# STM32MP25_CM33 register map
File version: 1.3
CPU: CM33 r0p1, little endian, MPU, FPU, vendor SysTick, 8 interrupt priority bits
Registers are 32-bit, read-write, reset 0x0 unless marked. A register's access mark holds for its fields unless they carry their own. Offsets are from the block's base; [hi:lo] are bit positions; {n}, {i} and the like mark numbered series.

## USB3DR (part 4 of 4) — USB3DR register block
Base 0x48300000
Same registers: USB3DR_S 0x58300000
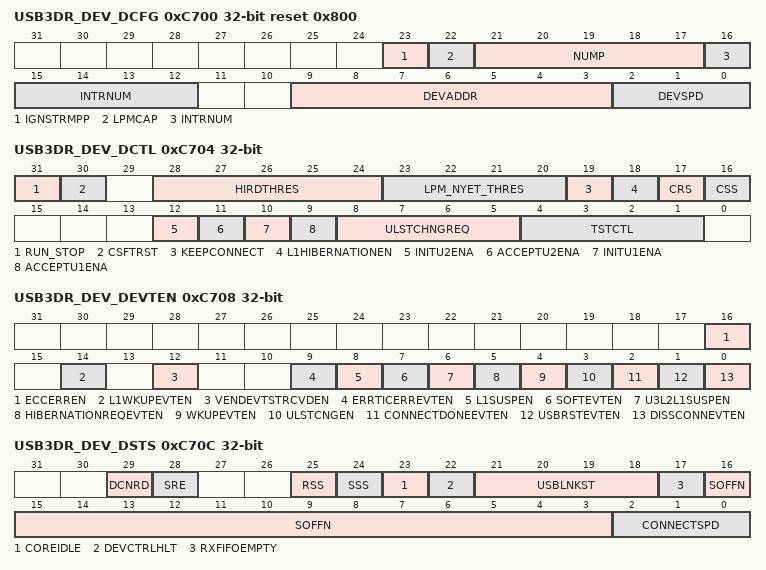
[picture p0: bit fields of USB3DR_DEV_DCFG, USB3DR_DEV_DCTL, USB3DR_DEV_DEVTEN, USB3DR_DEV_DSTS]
0xC700 USB3DR_DEV_DCFG reset 0x800 (reset mask 0x7F000C00) — USB3DR device configuration register
  [23] IGNSTRMPP — IgnoreStreamPP This bit only affects stream-capable bulk endpoints. When this bit is set to 0 and the controller receives a data packet with the packet pending (PP) bit set to 0 for OUT endpoints, or it receives an ACK with the NumP field set to 0 and PP set to 0 for IN endpoints, the core attempts to search for another stream (CStream) to initiate to the host. However, there are two situations where this behavior is not optimal: When the host is setting PP=0 even though it has not finished the stream, or When the endpoint on the device is configured with one transfer resource and therefore does not have any other streams to initiate to the host. When this bit is set to 1, the core ignores the packet pending bit for the purposes of stream selection and does not search for another stream when it receives DP(PP=0) or ACK(NumP=0, PP=0). This can enhance the performance when the device system bus bandwidth is low or the host responds to the core's ERDY transmission very quickly.
  [22] LPMCAP — LPM capable The application uses this bit to control the USB3DR LPM capabilities. If the USB3DR operates as a non-LPM-capable device, it cannot respond to LPM transactions.
    0=LPM capability is not enabled; 1=LPM capability is enabled
  [21:17] NUMP — Number of receive buffers. This bit indicates the number of receive buffers to be reported in the ACK TP. The USB3DR controller uses this field for non-control endpoints if GRXTHRCFG.UsbRxPktCntSel is set to 0. The application can program this value based on RxFIFO size, buffer sizes programmed in descriptors, and system latency. For an OUT endpoint, this field controls the number of receive buffers reported in the NumP field of the ACK TP transmitted by the core. Note: This bit is used in host mode when debug capability is enabled.
  [16:12] INTRNUM — Interrupt number Indicates interrupt/EventQ number on which non-endpoint-specific device-related interrupts (see DEVT) are generated.
  [9:3] DEVADDR — Device address. The application must perform the following: Program this field after every SetAddress request. Reset this field to zero after USB reset.
  [2:0] DEVSPD — Device speed. Indicates the speed at which the application requires the core to connect, or the maximum speed the application can support. However, the actual bus speed is determined only after the chirp sequence is completed, and is based on the speed of the USB host to which the core is connected.
    4=SuperSpeed (USB 3.0 PHY clock is 125MHz or 250MHz); 0=High-speed (USB 2.0 PHY clock is 30MHz or 60MHz); 1=Full-speed (USB 2.0 PHY clock is 30MHz or 60MHz)
0xC704 USB3DR_DEV_DCTL (reset mask 0x2000E001) — USB3DR device control register
  [31] RUN_STOP — Run/stop The software writes 1 to this bit to start the device controller operation. To stop the device controller operation, the software must remove any active transfers and write 0 to this bit. When the controller is stopped, it sets the DSTS.DevCtrlHlt bit when the core is idle and the lower layer finishes the disconnect process. The run/stop bit must be used in following cases as specified: After power-on reset and CSR initialization, the software must write 1 to this bit to start the device controller. The controller does not signal connection to the host until this bit is set. The software uses this bit to control the device controller to perform a soft disconnect. When the software writes 0 to this bit, the host does not see that the device is connected. The device controller stays in the disconnected state until the software writes 1 to this bit. The minimum duration of keeping this bit cleared is specified in the Note: below. If the software attempts a connect after the soft disconnect or detects a disconnect event, it must set DCTL[8:5] to 5 before reasserting the run/stop bit. When the USB or Link is in a lower power state and the two power rails configuration is selected, software writes 0 to this bit to indicate that it is going to turn off the core power rail. After the software turns on the core power rail again and re-initializes the device controller, it must set this bit to start the device controller. Note: The following is the minimum duration under various conditions for which the soft disconnect (SftDiscon) bit must be set for the USB host to detect a device disconnect: Note: 30ms: For SuperSpeed, when the device state is suspended, idle, transmit, or receive. Note: 10ms: For high-speed, when the device state is suspended, idle, or not idle/suspended (performing transactions). Note: For full-speed/low-speed, when the device state is suspended, idle, or not idle/supended (performing transactions). Note: To accommodate clock jitter, it is recommended that the application adds extra delay to the specified minimum duration.
  [30] CSFTRST — Core soft reset Resets the all clock domains as follows: This bit clears the interrupts and all the CSRs except GSTS, GSNPSID, GGPIO, GUID, GUSB2PHYCFGn registers, GUSB3PIPECTLn registers, DCFG, DCTL, DEVTEN, and DSTS registers. All module state machines (except the device bus slave unit) are reset to the idle state, and all the TxFIFOs and the RxFIFO are flushed. Any transactions on the device bus master are terminated as soon as possible, after gracefully completing the last data phase of a device bus transfer. Any transactions on the USB are terminated immediately. The application can write this bit at any time to reset the core. This is a self-clearing bit; the core clears this bit after all necessary logic is reset in the core, which may take several clocks depending on the core current state. Once this bit is cleared, the software must wait at least 3 PHY clocks before accessing the PHY domain (synchronization delay). Typically, software reset is used during software development and also when the PHY selection bits are dynamically changed in the USB configuration registers listed above. When the PHY is changed, the corresponding clock for the PHY is selected and used in the PHY domain. Once a new clock is selected, the PHY domain must be reset for proper operation. Note: Programming this field with random data causes side effect. Bit bash register testing is not recommended.
  [28:24] HIRDTHRES — HIRD threshold (HIRD_Thres) The core asserts output signals utmi_l1_suspend_n and utmi_sleep_n on the basis of this signal: The core asserts utmi_l1_suspend_n to put the PHY into deep Low-power mode in L1 when both of the following are true: HIRD value is greater than or equal to the value in DCTL.HIRD_Thres[3:0] HIRD_Thres[4] is set to 1. The core asserts utmi_sleep_n on L1 when one of the following is true: If the HIRD value is less than HIRD_Thres[3:0] or HIRD_Thres[4] is set to 0. Note: This field must be set to 0 during SuperSpeed mode of operation.
  [23:20] LPM_NYET_THRES — LPM NYET threshold When LPM errata is enabled: Bits [23:20]: LPM NYET response threshold (LPM_NYET_thres) Handshake response to LPM token specified by device application. Response depends on DCFG.LPMCap. DCFG.LPMCap is 0 - The core always responds with timeout (that is, no response). DCFG.LPMCap is 1 - The core responds with an ACK on successful LPM transaction, which requires that all of the following are satisfied: There are no PID or CRC5 errors in both the EXT token and the LPM token (if not true, inactivity results in a timeout ERROR). No data is pending in the TxFIFO and RxFIFO is empty (else NYET). The BESL value in the LPM token is less than or equal to LPM_NYET_thres[3:0]
  [19] KEEPCONNECT — Keep connect When 1, this bit enables the save and restore programming model by preventing the core from disconnecting from the host when DCTL.RUN_STOP is set to 0. It also enables the hibernation request event to be generated when the link goes to U3 or L2. The device core disconnects from the host when DCTL.RUN_STOP is set to 0. This bit indicates whether to preserve this behavior (0), or if the core must not disconnect when run/stop is set to 0 (1). This bit also prevents the LTSSM from automatically going to U0/L0 when the host requests resume from U3/L2. Note: If hibernation is disabled, that is, GCTL[1].GblHibernationEn=0, this bit is tied to zero.
  [18] L1HIBERNATIONEN — L1HibernationEn When this bit is set along with KeepConnect, the device core generates a hibernation request event if L1 is enabled and the HIRD value in the LPM token is larger than the threshold programmed in DCTL.HIRD_Thres. The core does not exit the LPM L1 state until the software writes recovery into the DCTL.ULStChngReq field. This prevents corner cases where the device is entering hibernation at the same time the host is attempting to exit L1. Note: If hibernation is disabled, that is, GCTL[1].GblHibernationEn=0, this bit is tied to zero.
  [17] CRS — Controller restore state (CRS) This command is similar to the USBCMD.CRS bit in host mode and initiates the restore process. When software sets this bit to 1, the controller immediately sets DSTS.RSS to 1. When the controller has finished the restore process, it sets DSTS.RSS to 0. Note: When read, this field always returns 0.
  [16] CSS — Controller save state (CSS) This command is similar to the USBCMD.CSS bit in host mode and initiates the save process. When the software sets this bit to 1, the controller immediately sets DSTS.SSS to 1. When the controller has finished the save process, it sets DSTS.SSS to 0' Note: When read, this field always returns 0.
  [12] INITU2ENA — Initiate U2 enable On USB reset, the hardware clears this bit to 0. The software sets this bit after receiving SetFeature(U2_ENABLE), and clears this bit when ClearFeature(U2_ENABLE) is received. If DCTL[11] (AcceptU2Ena) is 0, the link immediately exits U2 state.
    0=May not initiate U2 (default); 1=May initiate U2
  [11] ACCEPTU2ENA — Accept U2 enable On USB reset, the hardware clears this bit to 0. The software sets this bit after receiving a SetConfiguration command.
    0=The core reject U2 except when Force_LinkPM_Accept bit is set (default); 1=The core accepts transition to U2 state if nothing is pending on the application side
  [10] INITU1ENA — Initiate U1 enable On USB reset, the hardware clears this bit to 0. The software sets this bit after receiving SetFeature(U1_ENABLE), and clears this bit when ClearFeature(U1_ENABLE) is received. If DCTL[9] (AcceptU1Ena) is 0, the link immediately exits U1 state.
    0=May not initiate U1 (default);; 1=May initiate U1
  [9] ACCEPTU1ENA — Accept U1 enable On USB reset, the hardware clears this bit to 0. The software sets this bit after receiving a SetConfiguration command.
    0=The core rejects U1 except when Force_LinkPM_Accept bit is set (default); 1=The core accepts transition to U1 state if nothing is pending on the application side
  [8:5] ULSTCHNGREQ wo — ULSTCHNGREQ Software writes this field to issue a USB/Link state change request. A change in this field indicates a new request to the core. If the software wants to issue the same request back-to-back, it must write a 0 to this field between the two requests. The result of the state change request is reflected in the USB/Link state in DSTS. These bits are self-cleared on the MAC layer exiting suspended state. If the software is updating other fields of the DCTL register and not intending to force any link state change, then it must write a 0 to this field. SS Compliance mode is normally entered and controlled by the remote link partner. Refer to [USB3]. Alternatively, the local link can be forced directly into compliance mode, by resetting the SS link with the run/stop bit set to zero. If 10 is then written to the USB/Link state change field and 1 to run/stop, the link goes to compliance mode. Once in compliance, zero and 10 may be alternatively written to this field to advance the compliance pattern. Condition: in SS mode, the values for link state transition/action are: Others: Reserved Condition: in HS/FS/LS mode, the values for link state transition/action are: Others: Reserved The remote wakeup request must be issued 2us after the device goes into suspend state (DSTS[21:18] is 3. Note: After coming out of hibernation, the software must write 8 (recovery) into this field to confirm exit from the suspended state.
    0=No action; 2=Compliance
  [4:1] TSTCTL — Test control Others: Reserved
    0=Test mode disabled; 1=Test_J mode; 2=Test_K mode; 3=Test_SE0_NAK mode; 4=Test_Packet mode; 5=Test_Force_Enable
0xC708 USB3DR_DEV_DEVTEN (reset mask 0xFFFE0C00) — USB3DR device event enable register
  [16] ECCERREN ro — ECC error enable. If this bit is set to 1, the controller reports an ECC error to the software when an uncorrectable ECC occurs internally.
  [14] L1WKUPEVTEN — L1 resume detected event enable. Note: If GUCTL1[DEV_DECOUPLE_L1L2_EVT] is enabled, then this bit is for L1 resume detected event enable.
  [12] VENDEVTSTRCVDEN — Vendor device Test LMP received event (VndrDevTstRcvedEn)
  [9] ERRTICERREVTEN — Erratic error event enable
  [8] L1SUSPEN — L1 suspend event enable Note: Only if GUCTL1[DEV_DECOUPLE_L1L2_EVT] is enabled, this bit is for L1 suspend event enable.
  [7] SOFTEVTEN — Start of (u)frame
  [6] U3L2L1SUSPEN — U3/L2 or U3/L2L1 suspend event enable. Note: If GUCTL1[DEV_DECOUPLE_L1L2_EVT] is enabled, then this bit is for U3/L2 suspend event enable. Note: If GUCTL1[DEV_DECOUPLE_L1L2_EVT] is not enabled, then this bit is for U3/L2L1 suspend event enable.
  [5] HIBERNATIONREQEVTEN — This bit enables/disables the generation of the hibernation request event.
  [4] WKUPEVTEN — U3/L2 or U3/L2L1 resume detected event enable. Note: If GUCTL1[DEV_DECOUPLE_L1L2_EVT] is enabled, then this bit is for U3/L2 resume detected event enable. Note: If GUCTL1[DEV_DECOUPLE_L1L2_EVT] is not enabled, then this bit is for U3/L2L1 resume detected event enable.
  [3] ULSTCNGEN — USB/Link state change event enable
  [2] CONNECTDONEEVTEN — Connection done enable
  [1] USBRSTEVTEN — USB reset enable
  [0] DISSCONNEVTEN — Disconnect detected event enable
0xC70C USB3DR_DEV_DSTS (reset mask 0xDC000000) — USB3DR device status register
  [29] DCNRD ro — Device controller not ready The bit indicates that the core is in the process of completing the state transitions after exiting from hibernation. To complete the state transitions, it takes 256 bus clock cycles from the time DCTL[31].RUN_STOP is set. During hibernation, if the UTMI/ULPI PHY is in suspended state, then the 256-bus clock cycle delay starts after the PHY exited suspended state. The software must set DCTL[31].RUN_STOP to 1 and wait for this bit to be de-asserted to zero before processing DSTS.USBLnkSt. This bit is valid only when USB3DR_EN_PWROPT is set to 2 and GCTL[1].GblHibernationEn=1.
  [28] SRE — Save restore error Currently not supported.
  [25] RSS ro — RSS restore state status This bit is similar to the USBSTS.RSS in Host mode. When the controller finishes the restore process, it completes the command by setting DSTS.RSS to 0.
  [24] SSS ro — SSS save state status This bit is similar to the USBSTS.SSS in Host mode. When the controller has finished the save process, it completes the command by setting DSTS.SSS to 0.
  [23] COREIDLE ro — Core idle The bit indicates that the core finished transferring all RxFIFO data to system memory, writing out all completed descriptors, and all event counts are zero. Note: While testing for reset values, mask out the read value. This bit represents the changing state of the core and does not hold a static value.
  [22] DEVCTRLHLT ro — Device controller halted This bit is set to 0 when the run/stop bit in the DCTL register is set to 1. The core sets this bit to 1 when, after the software sets run/stop to 0, the core is idle and the lower layer finishes the disconnect process. When Halted=1, the core does not generate Device events. Note: The core does not set this bit to 1 if GEVNTCOUNTn has some valid value. Software needs to acknowledge the events that are generated (by writing to GEVNTCOUNTn) while it is waiting for this bit to be set to 1. Note: When interrupt moderation is enabled, there may be delay in raising the interrupt line when the event count is non-zero. Software should read the GEVNTCOUNT register directly and acknowledge them.
  [21:18] USBLNKST ro — USBLNKST USB/Link state Condition: in HS FS LS mode: The link state resume/reset indicates that the core received a resume or USB reset request from the host while the link was in hibernation. The software must write 8 (recovery) to the DCTL.ULStChngReq field to acknowledge the resume/reset request. When hibernation is enabled, GCTL[1].GblHibernationEn=1, this field USBLnkSt is valid only when DCTL[31].RUN_STOP is set to 1 and DSTS[29].DCNRD=0. Note: If SSIC is enabled, while exiting a low power state, the USBLnkSt field indicates resume/reset even for a disconnect condition because a resume precedes the disconnect.
    0=B_0x0_IN_SS_MODE_LTSSM_STATE (On state); 1=B_0x1_IN_SS_MODE_LTSSM_STATE (U1); 2=B_0x2_IN_SS_MODE_LTSSM_STATE (Sleep (L1) state); 3=B_0x3_IN_SS_MODE_LTSSM_STATE (Suspend (L2) state); 4=B_0x4_IN_SS_MODE_LTSSM_STATE (Disconnected state (default state)); 5=B_0x5_IN_SS_MODE_LTSSM_STATE (Early suspend state (valid only when hibernation is disabled, GCTL[1].GblHibernationEn=0)); 6=B_0x6_IN_SS_MODE_LTSSM_STATE (SS_INACT); 7=B_0x7_IN_SS_MODE_LTSSM_STATE (POLL); 8=B_0x8_IN_SS_MODE_LTSSM_STATE (RECOV); 9=B_0x9_IN_SS_MODE_LTSSM_STATE (HRESET); 10=B_0xA_IN_SS_MODE_LTSSM_STATE (CMPLY); 11=B_0xB_IN_SS_MODE_LTSSM_STATE (LPBK); 15=B_0xF_IN_SS_MODE_LTSSM_STATE (Resume (valid only when hibernation is enabled, GCTL[1].GblHibernationEn=1)); 14=B_0xE_IN_SS_MODE_LTSSM_STATE (Reset (valid only when hibernation is enabled, GCTL[1].GblHibernationEn=1))
  [17] RXFIFOEMPTY ro
  [16:3] SOFFN ro — Frame/Microframe number of the received SOF. When the core is operating at SuperSpeed, [16:3] indicates the uframe/ITP number When the core is operating at high-speed, [16:6] indicates the frame number [5:3] indicates the micro-frame number When the core is operating at full-speed, [16:14] is not used, the software can ignore these 3 bits [13:3] indicates the frame number
  [2:0] CONNECTSPD ro — Connected speed (ConnectSpd) Indicates the speed at which the USB3DR has come up after speed detection through a chirp sequence. Low-speed is not supported for devices using a UTMI+ PHY.
    4=SuperSpeed (PHY clock is running at 125 or 250MHz); 0=High-speed (PHY clock is running at 30 or 60MHz); 1=Full-speed (PHY clock is running at 30 or 60MHz)
0xC710 USB3DR_DEV_DGCMDPAR — USB3DR device generic command parameter register
  [31:0] PARAMETER
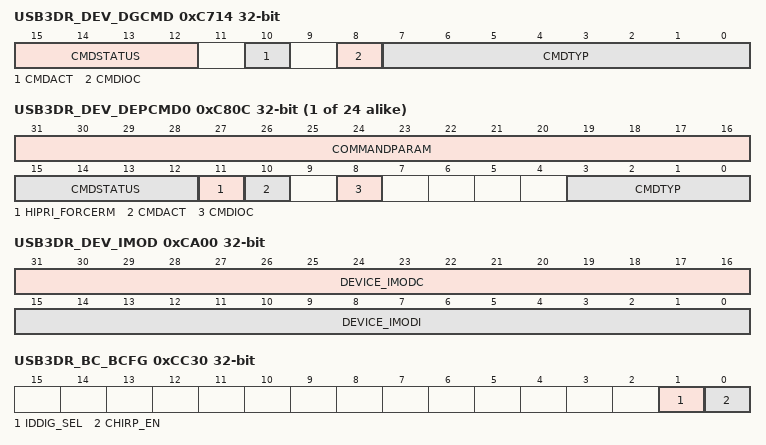
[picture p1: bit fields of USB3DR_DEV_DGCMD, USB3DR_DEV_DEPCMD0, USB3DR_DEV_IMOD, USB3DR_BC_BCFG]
0xC714 USB3DR_DEV_DGCMD (reset mask 0xFFFF0A00) — USB3DR device generic command register
  [15:12] CMDSTATUS ro — Command status
    1=CmdErr, indicates that the device controller encountered an error while processing the command; 0=Indicates command success
  [10] CMDACT — Command active The software sets this bit to 1 to enable the device controller to execute the generic command. The device controller sets this bit to 0 after executing the command.
  [8] CMDIOC — Command interrupt on complete When this bit is set, the device controller issues a generic command completion event after executing the command. Note: This interrupt is mapped to DCFG.IntrNum. Note: This field must not set to 1 if the DCTL.RUN_STOP field is 0.
  [7:0] CMDTYP — Generic command type Specifies the type of generic command the software driver is requesting the controller to perform. All other values are reserved.
    2=Set periodic parameters; 4=Set scratchpad buffer array address low; 5=Set scratchpad buffer array address high; 7=Transmit device notification; 9=Selected FIFO flush; 10=All FIFO flush; 12=Set endpoint NRDY; 16=Run device bus loopback test; 17=Restart after disconnect
0xC720 USB3DR_DEV_DALEPENA — USB3DR device active USB endpoint enable register
  [31:0] USBACTEP — USBACTEP USB active endpoints (USBActEP) This field indicates if a USB endpoint is active in the current configuration and interface. It applies to USB IN endpoints 0.15 and OUT endpoints 0.15, with one bit for each of the 32 possible endpoints. Even numbers are for USB OUT endpoints, and odd numbers are for USB IN endpoints, as follows: Bit[0]: USB EP0-OUT Bit[1]: USB EP0-IN Bit[2]: USB EP1-OUT Bit[3]: USB EP1-IN The entity programming this register must set bits 0 and 1 because they enable control endpoints that map to physical endpoints (resources) after USBReset. Hardware clears these bits for all endpoints (other than EP0-OUT and EP0-IN) after detecting a USB reset event. After receiving SetConfiguration and SetInterface requests, the application must program endpoint registers accordingly and set these bits.
0xC800 USB3DR_DEV_DEPCMDPAR20 — USB3DR device physical endpoint-n command parameter 2 register
  [31:0] PARAMETER
0xC804 USB3DR_DEV_DEPCMDPAR10 — USB3DR device physical endpoint-n command parameter 1 register
  [31:0] PARAMETER
{0xC808+0x10*i} USB3DR_DEV_DEPCMDPAR{i:02} (i=0..9) — USB3DR device physical endpoint-n command parameter 0 register
  [31:0] PARAMETER
{0xC80C+0x10*i} USB3DR_DEV_DEPCMD{i} (i=0..23) — USB3DR device physical endpoint-n command register
  [31:16] COMMANDPARAM — Command parameters or event parameters Command parameters (CommandParam), when this register is written: For start transfer command: [31:16]: StreamID. The USB StreamID assigned to this transfer For start transfer command applied to an isochronous endpoint [31:16]: StartMicroFramNum: indicates the (micro-)frame number to which the first TRB applies. For update transfer, end transfer, and start new configuration commands [22:16]: Transfer resource index (XferRscIdx). The hardware-assigned transfer resource index for the transfer, which was returned in response to the start transfer command. The application software-assigned transfer resource index for a start new configuration command. Event parameters (EventParam), when this register is read.
  [15:12] CMDSTATUS — Command completion status (CmdStatus) Additional information about the completion of this command is available in this field. The information is in the same format as bits 15:12 of the endpoint command complete event.
  [11] HIPRI_FORCERM — HighPriority/ForceRM (HiPri_ForceRM) HighPriority: only valid for start transfer command ForceRM: only valid for end transfer command ClearPendIN: only valid for clear stall command. The software sets this bit to clear any pending IN transaction (on that endpoint) stuck at the lower layers when a clear stall command is issued.
  [10] CMDACT — Command active (CmdAct) Software sets this bit to 1 to enable the device endpoint controller to execute the generic command. The device controller sets this bit to 0 when the CmdStatus field is valid and the endpoint is ready to accept another command. This does not imply that all the effects of the previously-issued command have taken place.
  [8] CMDIOC — CMDIOC Command interrupt on complete (CmdIOC) When this bit is set, the device controller issues a generic endpoint command complete event after executing the command. Note: This interrupt is mapped to DEPCFG.IntrNum. When the DEPCFG command is executed, the command interrupt on completion goes to the interrupt pointed by the DEPCFG.IntrNum in the current command. Note: This field must not set to 1 if the DCTL.RUN_STOP field is 0.
  [3:0] CMDTYP — Command type Specifies the type of command the software driver is requesting the core to perform. 0x09 Start new configuration, no parameter needed
    1=Set endpoint configuration, 64 or 96-bit parameter; 2=Set endpoint transfer resource configuration, 32-bit parameter; 3=Get endpoint state, no parameter needed; 4=Set stall, no parameter needed; 5=Clear stall (see set stall), no parameter needed; 6=Start transfer, 64-bit parameter; 7=Update transfer, no parameter needed; 8=End transfer, no parameter needed
0xC810 USB3DR_DEV_DEPCMDPAR21 — USB3DR device physical endpoint-n command parameter 2 register
  [31:0] PARAMETER
0xC814 USB3DR_DEV_DEPCMDPAR11 — USB3DR device physical endpoint-n command parameter 1 register
  [31:0] PARAMETER
0xC820 USB3DR_DEV_DEPCMDPAR22 — USB3DR device physical endpoint-n command parameter 2 register
  [31:0] PARAMETER
0xC824 USB3DR_DEV_DEPCMDPAR12 — USB3DR device physical endpoint-n command parameter 1 register
  [31:0] PARAMETER
0xC830 USB3DR_DEV_DEPCMDPAR23 — USB3DR device physical endpoint-n command parameter 2 register
  [31:0] PARAMETER
0xC834 USB3DR_DEV_DEPCMDPAR13 — USB3DR device physical endpoint-n command parameter 1 register
  [31:0] PARAMETER
{0xC6C0+0x10*i} USB3DR_DEV_DEPCMDPAR{i} (i=24..29) — USB3DR device physical endpoint-n command parameter 2 register
  [31:0] PARAMETER
0xC844 USB3DR_DEV_DEPCMDPAR14 — USB3DR device physical endpoint-n command parameter 1 register
  [31:0] PARAMETER
0xC854 USB3DR_DEV_DEPCMDPAR15 — USB3DR device physical endpoint-n command parameter 1 register
  [31:0] PARAMETER
0xC864 USB3DR_DEV_DEPCMDPAR16 — USB3DR device physical endpoint-n command parameter 1 register
  [31:0] PARAMETER
0xC874 USB3DR_DEV_DEPCMDPAR17 — USB3DR device physical endpoint-n command parameter 1 register
  [31:0] PARAMETER
0xC884 USB3DR_DEV_DEPCMDPAR18 — USB3DR device physical endpoint-n command parameter 1 register
  [31:0] PARAMETER
0xC894 USB3DR_DEV_DEPCMDPAR19 — USB3DR device physical endpoint-n command parameter 1 register
  [31:0] PARAMETER
{0xBB80+0x10*i} USB3DR_DEV_DEPCMDPAR{i} (i=210..223) — USB3DR device physical endpoint-n command parameter 2 register
  [31:0] PARAMETER
{0xC1C4+0x10*i} USB3DR_DEV_DEPCMDPAR{i} (i=110..123) — USB3DR device physical endpoint-n command parameter 1 register
  [31:0] PARAMETER
0xC8A8 USB3DR_DEV_DEPCMDPAR010 — USB3DR device physical endpoint-n command parameter 0 register
  [31:0] PARAMETER
0xC8B8 USB3DR_DEV_DEPCMDPAR011 — USB3DR device physical endpoint-n command parameter 0 register
  [31:0] PARAMETER
0xC8C8 USB3DR_DEV_DEPCMDPAR012 — USB3DR device physical endpoint-n command parameter 0 register
  [31:0] PARAMETER
0xC8D8 USB3DR_DEV_DEPCMDPAR013 — USB3DR device physical endpoint-n command parameter 0 register
  [31:0] PARAMETER
0xC8E8 USB3DR_DEV_DEPCMDPAR014 — USB3DR device physical endpoint-n command parameter 0 register
  [31:0] PARAMETER
0xC8F8 USB3DR_DEV_DEPCMDPAR015 — USB3DR device physical endpoint-n command parameter 0 register
  [31:0] PARAMETER
0xC908 USB3DR_DEV_DEPCMDPAR016 — USB3DR device physical endpoint-n command parameter 0 register
  [31:0] PARAMETER
0xC918 USB3DR_DEV_DEPCMDPAR017 — USB3DR device physical endpoint-n command parameter 0 register
  [31:0] PARAMETER
0xC928 USB3DR_DEV_DEPCMDPAR018 — USB3DR device physical endpoint-n command parameter 0 register
  [31:0] PARAMETER
0xC938 USB3DR_DEV_DEPCMDPAR019 — USB3DR device physical endpoint-n command parameter 0 register
  [31:0] PARAMETER
0xC948 USB3DR_DEV_DEPCMDPAR020 — USB3DR device physical endpoint-n command parameter 0 register
  [31:0] PARAMETER
0xC958 USB3DR_DEV_DEPCMDPAR021 — USB3DR device physical endpoint-n command parameter 0 register
  [31:0] PARAMETER
0xC968 USB3DR_DEV_DEPCMDPAR022 — USB3DR device physical endpoint-n command parameter 0 register
  [31:0] PARAMETER
0xC978 USB3DR_DEV_DEPCMDPAR023 — USB3DR device physical endpoint-n command parameter 0 register
  [31:0] PARAMETER
0xCA00 USB3DR_DEV_IMOD — USB3DR device interrupt moderation register
  [31:16] DEVICE_IMODC — Interrupt moderation down counter Loaded with the DEVICE_IMODI value, whenever the hardware interrupt(n) line is de-asserted from the asserted state, counts down to 0, and stops. The interrupt(n) is signaled whenever this counter is 0, EVNT_HANDLER_BUSY is 0, and there are pending events (that is, event count is non-zero). This counter may be directly written by software at any time to alter the interrupt rate.
  [15:0] DEVICE_IMODI — Moderation interval (DEVICE_IMODI) This field holds the minimum inter-interrupt interval between events. The interval is specified in 250ns increments. A value of 0 disables the interrupt throttling logic and interrupts are generated immediately if event count becomes non-zero. In scale down simulation mode, 4 ram clocks are used to time 250ns.
0xCC30 USB3DR_BC_BCFG (reset mask 0xFFFFFFFC) — USB3DR battery charger configuration register
  [1] IDDIG_SEL — IDDIG select When this bit is programmed as: When ULPI PHY is used, IDDIG_SEL needs to be programmed to 0 always, so that the core uses the ID value obtained from the RX_CMD.
    1=The core determines the ID pin value from RID_A and RID_GND inputs of the battery charger; 0=The core determines ID pin value from utmiotg_iddig input
  [0] CHIRP_EN — Chirp enable When this bit is 1, the core asserts the bc_chirp_on output signal to indicate an imminent chirp.
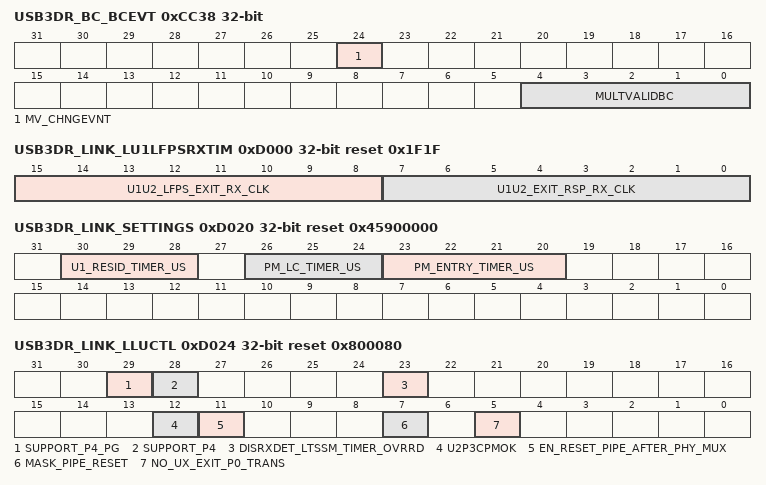
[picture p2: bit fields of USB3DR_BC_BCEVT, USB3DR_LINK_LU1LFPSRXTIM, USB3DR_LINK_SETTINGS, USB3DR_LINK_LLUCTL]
0xCC38 USB3DR_BC_BCEVT — USB3DR battery charger event register
  [24] MV_CHNGEVNT — Multi-valued input changed event: This event indicates that there is a change in the value of at least one ACA pin value. This bit is present only if USB3DR_EN_BC=1, otherwise it is Reserved.
  [4:0] MULTVALIDBC ro — Multi valued ID pin Indicates the battery charger ACA inputs. MultValIdBc[4]: bc_rid_float MultValIdBc[3]: bc_rid_gnd MultValIdBc[2]: bc_rid_a MultValIdBc[1]: bc_rid_b MultValIdBc[0]: bc_rid_c
0xCC3C USB3DR_BC_BCEVTEN (reset mask 0xFEFFFFFF) — USB3DR battery charger event enable register
  [24] MV_CHNGEVNTENA — BCEvtInfoEna[0] Multi-valued input changed event enable (MV_ChngEvntEn) When this bit is set, MV_ChngEvnt in BCEVT register is enabled.
0xD000 USB3DR_LINK_LU1LFPSRXTIM reset 0x1F1F — USB3DR U1/U2 LFPS RX timer register
  [15:8] U1U2_LFPS_EXIT_RX_CLK — Programmable U1U2 LFPS EXIT RX CLKS Applicable to remote partner initiated Ux exit: time to recognize valid Ux exit request from the remote partner. This field is encoded as the pipe clk (8ns) count for the LFPS.
    1=8ns
  [7:0] U1U2_EXIT_RSP_RX_CLK — Programmable U1U2 EXIT RESP RX CLKS Applicable to locally initiated Ux exit: minimum LFPS reception from remote to consider Ux exit handshake is successful. This field is encoded as the pipe clk (8ns) count for the LFPS.
    1=8ns
0xD020 USB3DR_LINK_SETTINGS reset 0x45900000 — USB3DR link setting register
  [30:28] U1_RESID_TIMER_US — Programmable U1 MIN RESIDENCY TIMER This field specifies U1 MIN RESIDENCY TIMER value in us. Set to 0 to disable the timer.
  [26:24] PM_LC_TIMER_US — Programmable PM_LC_TIMER This field specifies PM_LC_TIMER value in us.
  [23:20] PM_ENTRY_TIMER_US — Programmable PM_ENTRY_TIMER This field specifies PM_ENTRY_TIMER value in us.
0xD024 USB3DR_LINK_LLUCTL reset 0x800080 — USB3DR link user control register
  [29] SUPPORT_P4_PG — PHY P4 power gate mode (PG) is enabled. Set this bit if the PHY supports PG mode in P4. This bit is used only for Synopsys PHY.
  [28] SUPPORT_P4 — Support PHY P3.CPM and P4 power states. When this bit is set, the controller puts the PHY in P3.CPM or P4 in certain states. This bit is used only for Synopsys PHY.
  [23] DISRXDET_LTSSM_TIMER_OVRRD — DisRxDet_LTSSM_Timer_Ovrrd. When DisRxDetU3RxDet is asserted in polling or U1, the timeout expires immediately.
  [12] U2P3CPMOK — P3CPM OK for U2/SSInactive (U2P3CPMok) Note: For a port, if both GUCTL1[25]=1 and LUCTL[12]=1, LUCTL[12]=1 takes priority.
    0=During link state U2/SS.Inactive, put PHY in P2 (default); 1=During link state U2/SS.Inactive, put PHY in P3CPM
  [11] EN_RESET_PIPE_AFTER_PHY_MUX — en_reset_pipe_after_phy_mux. The controller issues USB 3.0 PHY reset after DisRxDetU3RxDet is de-asserted.
  [7] MASK_PIPE_RESET — Mask pipe reset. If this bit is set, controller blocks pipe_reset_n from going to the PHY when DisRxDetU3RxDet=1.
  [5] NO_UX_EXIT_P0_TRANS — no_ux_exit_p0_trans. Link LTSSM detects Ux_exit LFPS when P0 transition is on-going by default. If this bit is set, Link LTSSM may miss Ux_exit LFPS when P0 transition is happening.
0xD028 USB3DR_LINK_LPTMDPDELAY reset 0xC00 — USB3DR link datapath delay register
  [21:10] P3CPMP4_RESIDENCY — p3cpmp4 residency timer value. Minimum number of suspend_clk periods that the controller needs to stay in P3.CPM or P4 before exiting P3.CPM or P4. This field is used only for Synopsys PHY.
